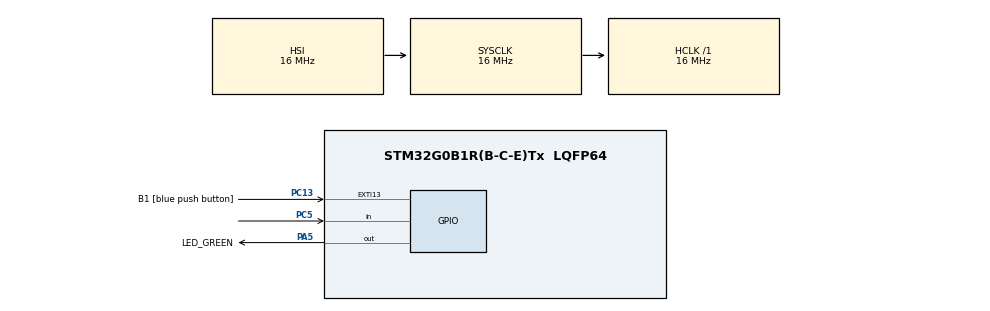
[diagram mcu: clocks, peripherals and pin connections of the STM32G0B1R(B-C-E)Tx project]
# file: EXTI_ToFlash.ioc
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Mcu.Family=STM32G0
Mcu.Name=STM32G0B1R(B-C-E)Tx
Mcu.Package=LQFP64
NVIC.EXTI4_15_IRQn=true\:0\:0\:false\:false\:true\:true\:true\:true
PA13.GPIO_Label=TMS
PA13.Signal=SYS_SWDIO
PA14-BOOT0.GPIO_Label=TCK
PA14-BOOT0.Signal=SYS_SWCLK
PA2.GPIO_Label=USART2_TX [STLK_TX]
PA2.Signal=USART2_TX
PA3.GPIO_Label=USART2_RX [STLK_RX]
PA3.Signal=USART2_RX
PA5.GPIO_Label=LED_GREEN
PA5.GPIO_Speed=GPIO_SPEED_FREQ_HIGH
PA5.Signal=GPIO_Output
PC13.GPIO_Label=B1 [blue push button]
PC13.Signal=GPXTI13
PC14-OSC32_IN\ (PC14).Signal=RCC_OSC32_IN
PC15-OSC32_OUT\ (PC15).Signal=RCC_OSC32_OUT
PC5.GPIO_PuPd=GPIO_PULLDOWN
PC5.Signal=GPIO_Input
PF0-OSC_IN\ (PF0).GPIO_Label=MCO
PF0-OSC_IN\ (PF0).Signal=RCC_OSC_IN
ProjectManager.HeapSize=0x200
ProjectManager.StackSize=0x400
ProjectManager.TargetToolchain=STM32CubeIDE
RCC.AHBFreq_Value=16000000
RCC.CortexFreq_Value=16000000
RCC.EXTERNAL_CLOCK_VALUE=12288000
RCC.HCLKFreq_Value=16000000
RCC.HSE_VALUE=8000000
RCC.HSI48_VALUE=48000000
RCC.HSI_VALUE=16000000
RCC.LSE_VALUE=32768
RCC.SYSCLKFreq_VALUE=16000000
RCC.USBFreq_Value=48000000
RCC.VCOOutputFreq_Value=128000000
board=NUCLEO-G0B1RE

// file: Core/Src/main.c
/* USER CODE BEGIN Header */
/**
  ******************************************************************************
  * @file           : main.c
  * @brief          : Main program body
  ******************************************************************************
  * @attention
  *
  * Copyright (c) 2025 STMicroelectronics.
  * All rights reserved.
  *
  * This software is licensed under terms that can be found in the LICENSE file
  * in the root directory of this software component.
  * If no LICENSE file comes with this software, it is provided AS-IS.
  *
  ******************************************************************************
  */
/* USER CODE END Header */
#include "main.h"

/* USER CODE BEGIN PV */

uint32_t FirstPage = 0, NbOfPages = 0, BankNumber = 0;
uint32_t Address = 0, PageError = 0;

/*Variable used for Erase procedure*/
static FLASH_EraseInitTypeDef EraseInitStruct;

/* USER CODE END PV */

void SystemClock_Config(void);
static void MX_GPIO_Init(void);

void writeToFlash(uint32_t address, uint32_t data);
void eraseFlash(uint32_t startAddress, uint32_t endAddress);

static uint32_t GetPage(uint32_t Address);
static uint32_t GetBank(uint32_t Address);

GPIO_PinState Read_GPIO_Pin(GPIO_TypeDef* GPIOx, uint16_t GPIO_Pin);

/* USER CODE BEGIN 0 */

#define FLASH_DATA_SIZE 6
#define FLASH_START_ADDRESS 0x08010000  // Endereço inicial da memória Flash
#define FLASH_END_ADDRESS 0x080100A0

uint32_t flashAddress = FLASH_START_ADDRESS;
uint32_t dataToWrite = 0xFFFFFFFF;  // Dado a ser gravado
uint8_t dataIndex = 0;

/* USER CODE END 0 */

int main(void)
{

  /* MCU Configuration--------------------------------------------------------*/

  /* Reset of all peripherals, Initializes the Flash interface and the Systick. */
  HAL_Init();

  /* Configure the system clock */
  SystemClock_Config();

  /* Initialize all configured peripherals */
  MX_GPIO_Init();
  /* USER CODE BEGIN 2 */
  eraseFlash(FLASH_START_ADDRESS, (FLASH_START_ADDRESS + (FLASH_DATA_SIZE * 4)));
  /* USER CODE END 2 */

  /* Infinite loop */
  /* USER CODE BEGIN WHILE */
  while (1)
  {
	HAL_Delay(100);
    /* USER CODE END WHILE */

  }
}

void SystemClock_Config(void)
{
  RCC_OscInitTypeDef RCC_OscInitStruct = {0};
  RCC_ClkInitTypeDef RCC_ClkInitStruct = {0};

  /** Configure the main internal regulator output voltage
  */
  HAL_PWREx_ControlVoltageScaling(PWR_REGULATOR_VOLTAGE_SCALE1);

  /** Initializes the RCC Oscillators according to the specified parameters
  * in the RCC_OscInitTypeDef structure.
  */
  RCC_OscInitStruct.OscillatorType = RCC_OSCILLATORTYPE_HSI;
  RCC_OscInitStruct.HSIState = RCC_HSI_ON;
  RCC_OscInitStruct.HSIDiv = RCC_HSI_DIV1;
  RCC_OscInitStruct.HSICalibrationValue = RCC_HSICALIBRATION_DEFAULT;
  RCC_OscInitStruct.PLL.PLLState = RCC_PLL_NONE;
  if (HAL_RCC_OscConfig(&RCC_OscInitStruct) != HAL_OK)
  {
    Error_Handler();
  }

  /** Initializes the CPU, AHB and APB buses clocks
  */
  RCC_ClkInitStruct.ClockType = RCC_CLOCKTYPE_HCLK|RCC_CLOCKTYPE_SYSCLK
                              |RCC_CLOCKTYPE_PCLK1;
  RCC_ClkInitStruct.SYSCLKSource = RCC_SYSCLKSOURCE_HSI;
  RCC_ClkInitStruct.AHBCLKDivider = RCC_SYSCLK_DIV1;
  RCC_ClkInitStruct.APB1CLKDivider = RCC_HCLK_DIV1;

  if (HAL_RCC_ClockConfig(&RCC_ClkInitStruct, FLASH_LATENCY_0) != HAL_OK)
  {
    Error_Handler();
  }
}

static void MX_GPIO_Init(void)
{
  GPIO_InitTypeDef GPIO_InitStruct = {0};

  /* GPIO Ports Clock Enable */
  __HAL_RCC_GPIOC_CLK_ENABLE();
  __HAL_RCC_GPIOF_CLK_ENABLE();
  __HAL_RCC_GPIOA_CLK_ENABLE();

  /*Configure GPIO pin Output Level */
  HAL_GPIO_WritePin(LED_GREEN_GPIO_Port, LED_GREEN_Pin, GPIO_PIN_RESET);

  /*Configure GPIO pin : B1_Pin */
  GPIO_InitStruct.Pin = B1_Pin;
  GPIO_InitStruct.Mode = GPIO_MODE_IT_FALLING;
  GPIO_InitStruct.Pull = GPIO_NOPULL;
  HAL_GPIO_Init(B1_GPIO_Port, &GPIO_InitStruct);

  /*Configure GPIO pins : USART2_TX_Pin USART2_RX_Pin */
  GPIO_InitStruct.Pin = USART2_TX_Pin|USART2_RX_Pin;
  GPIO_InitStruct.Mode = GPIO_MODE_AF_PP;
  GPIO_InitStruct.Pull = GPIO_NOPULL;
  GPIO_InitStruct.Speed = GPIO_SPEED_FREQ_LOW;
  GPIO_InitStruct.Alternate = GPIO_AF1_USART2;
  HAL_GPIO_Init(GPIOA, &GPIO_InitStruct);

  /*Configure GPIO pin : LED_GREEN_Pin */
  GPIO_InitStruct.Pin = LED_GREEN_Pin;
  GPIO_InitStruct.Mode = GPIO_MODE_OUTPUT_PP;
  GPIO_InitStruct.Pull = GPIO_NOPULL;
  GPIO_InitStruct.Speed = GPIO_SPEED_FREQ_HIGH;
  HAL_GPIO_Init(LED_GREEN_GPIO_Port, &GPIO_InitStruct);

  /*Configure GPIO pin : PC5 */
  GPIO_InitStruct.Pin = GPIO_PIN_5;
  GPIO_InitStruct.Mode = GPIO_MODE_INPUT;
  GPIO_InitStruct.Pull = GPIO_PULLDOWN;
  HAL_GPIO_Init(GPIOC, &GPIO_InitStruct);

  /* EXTI interrupt init*/
  HAL_NVIC_SetPriority(EXTI4_15_IRQn, 2, 0);
  HAL_NVIC_EnableIRQ(EXTI4_15_IRQn);

}

/* USER CODE BEGIN 4 */
void writeToFlash(uint32_t address, uint32_t data) {

    HAL_FLASH_Unlock();

    HAL_FLASH_Program(FLASH_TYPEPROGRAM_DOUBLEWORD, address, data);

    HAL_FLASH_Lock();
}

GPIO_PinState Read_GPIO_Pin(GPIO_TypeDef* GPIOx, uint16_t GPIO_Pin) {
    return HAL_GPIO_ReadPin(GPIOx, GPIO_Pin);
}

void eraseFlash(uint32_t startAddress, uint32_t endAddress) {

	uint32_t pageError = 0;

    HAL_FLASH_Unlock();

    /* Clear OPTVERR bit set on virgin samples */
      __HAL_FLASH_CLEAR_FLAG(FLASH_FLAG_OPTVERR);

      /* Erase the user Flash area
        (area defined by FLASH_USER_START_ADDR and FLASH_USER_END_ADDR) ***********/

      /* Get the 1st page to erase */
      FirstPage = GetPage(FLASH_START_ADDRESS);

      /* Get the number of pages to erase from 1st page */
      NbOfPages = GetPage(FLASH_END_ADDRESS) - FirstPage + 1;

      /* Get the bank */
      BankNumber = GetBank(FLASH_START_ADDRESS);

    EraseInitStruct.TypeErase = FLASH_TYPEERASE_PAGES;
    EraseInitStruct.Banks = BankNumber;
    EraseInitStruct.Page = FirstPage;
    EraseInitStruct.NbPages = NbOfPages;

    HAL_FLASHEx_Erase(&EraseInitStruct, &pageError);

    HAL_FLASH_Lock();
}

static uint32_t GetPage(uint32_t Addr)
{
  uint32_t page = 0;

  if (Addr < (FLASH_BASE + FLASH_BANK_SIZE))
  {
    /* Bank 1 */
    page = (Addr - FLASH_BASE) / FLASH_PAGE_SIZE;
  }
  else
  {
    /* Bank 2 */
    page = (Addr - (FLASH_BASE + FLASH_BANK_SIZE)) / FLASH_PAGE_SIZE;
  }

  return page;
}

static uint32_t GetBank(uint32_t Addr)
{
  return FLASH_BANK_1;
}

void HAL_GPIO_EXTI_Falling_Callback(uint16_t GPIO_Pin)
{
	if(GPIO_Pin == B1_Pin)
	{
		if (dataIndex < FLASH_DATA_SIZE) {

				 GPIO_PinState pinState = Read_GPIO_Pin(GPIOC, GPIO_PIN_5);
				 dataToWrite = pinState;

				 // Piscar o LED durante a gravação

				    HAL_GPIO_WritePin(GPIOA, LED_GREEN_Pin, GPIO_PIN_SET);
					writeToFlash(flashAddress, dataToWrite);
					HAL_Delay(2000);

				 // Incrementar o endereço e o índice
					flashAddress+=8;
					dataIndex++;

					HAL_GPIO_WritePin(GPIOA, LED_GREEN_Pin, GPIO_PIN_RESET);
		}
	}
}

void EXTI0_1_IRQHandler(void) {
    HAL_GPIO_EXTI_IRQHandler(GPIO_PIN_13);
}
/* USER CODE END 4 */

void Error_Handler(void)
{
  __disable_irq();
  while (1)
  {
  }
}
